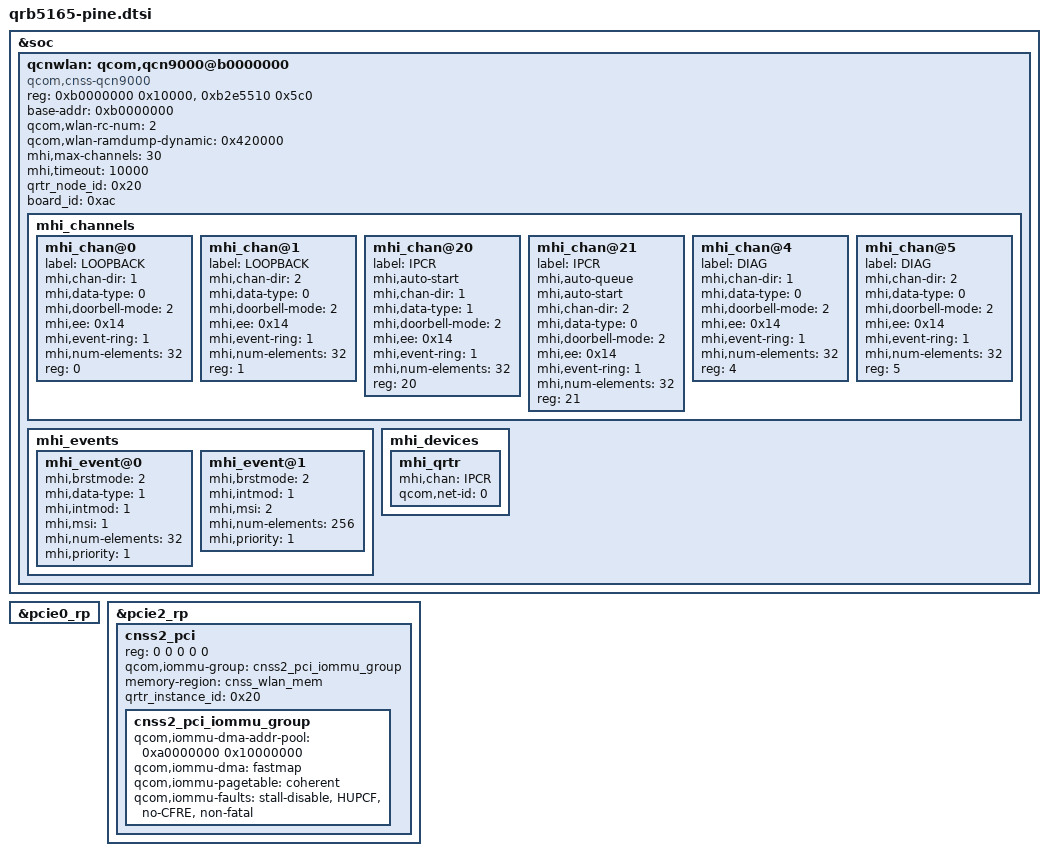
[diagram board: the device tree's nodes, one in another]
#include "qrb5165.dtsi"

&soc {
	qcnwlan: qcom,qcn9000@b0000000 {
		compatible = "qcom,cnss-qcn9000";
		reg = <0xb0000000 0x10000>,
		      <0xb2e5510 0x5c0>;
		reg-names = "smmu_iova_ipa", "tcs_cmd";
		base-addr = <0xb0000000>;
		qcom,wlan-rc-num = <2>;
		qcom,wlan-ramdump-dynamic = <0x420000>;
		mhi,max-channels = <30>;
		mhi,timeout = <10000>;
		qrtr_node_id = <0x20>;
		board_id = <0xac>;
		status="okay";

		mhi_channels {
			#address-cells = <1>;
			#size-cells = <0>;

			mhi_chan@0 {
				label = "LOOPBACK";
				mhi,chan-dir = <1>;
				mhi,data-type = <0>;
				mhi,doorbell-mode = <2>;
				mhi,ee = <0x14>;
				mhi,event-ring = <1>;
				mhi,num-elements = <32>;
				reg = <0>;
			};

			mhi_chan@1 {
				label = "LOOPBACK";
				mhi,chan-dir = <2>;
				mhi,data-type = <0>;
				mhi,doorbell-mode = <2>;
				mhi,ee = <0x14>;
				mhi,event-ring = <1>;
				mhi,num-elements = <32>;
				reg = <1>;
			};

			mhi_chan@20 {
				label = "IPCR";
				mhi,auto-start;
				mhi,chan-dir = <1>;
				mhi,data-type = <1>;
				mhi,doorbell-mode = <2>;
				mhi,ee = <0x14>;
				mhi,event-ring = <1>;
				mhi,num-elements = <32>;
				reg = <20>;
			};

			mhi_chan@21 {
				label = "IPCR";
				mhi,auto-queue;
				mhi,auto-start;
				mhi,chan-dir = <2>;
				mhi,data-type = <0>;
				mhi,doorbell-mode = <2>;
				mhi,ee = <0x14>;
				mhi,event-ring = <1>;
				mhi,num-elements = <32>;
				reg = <21>;
			};

			mhi_chan@4 {
				label = "DIAG";
				mhi,chan-dir = <1>;
				mhi,data-type = <0>;
				mhi,doorbell-mode = <2>;
				mhi,ee = <0x14>;
				mhi,event-ring = <1>;
				mhi,num-elements = <32>;
				reg = <4>;
			};

			mhi_chan@5 {
				label = "DIAG";
				mhi,chan-dir = <2>;
				mhi,data-type = <0>;
				mhi,doorbell-mode = <2>;
				mhi,ee = <0x14>;
				mhi,event-ring = <1>;
				mhi,num-elements = <32>;
				reg = <5>;
			};
		};

		mhi_events {
			mhi_event@0 {
				mhi,brstmode = <2>;
				mhi,data-type = <1>;
				mhi,intmod = <1>;
				mhi,msi = <1>;
				mhi,num-elements = <32>;
				mhi,priority = <1>;
			};

			mhi_event@1 {
				mhi,brstmode = <2>;
				mhi,intmod = <1>;
				mhi,msi = <2>;
				mhi,num-elements = <256>;
				mhi,priority = <1>;
			};
		};

		mhi_devices {
			mhi_qrtr {
				mhi,chan = "IPCR";
				qcom,net-id = <0>;
			};
		};
	};
};

&pcie0_rp {
	/delete-node/ cnss_pci;
};

&pcie2_rp {
	#address-cells = <5>;
	#size-cells = <0>;
	status = "ok";

	/delete-node/ qcom,mhi@0;

	cnss2_pci: cnss2_pci {
		reg = <0 0 0 0 0>;
		qcom,iommu-group = <&cnss2_pci_iommu_group>;
		memory-region = <&cnss_wlan_mem>;
		qrtr_instance_id = <0x20>;
		status = "ok";

		#address-cells = <1>;
		#size-cells = <1>;

		cnss2_pci_iommu_group: cnss2_pci_iommu_group {
			qcom,iommu-dma-addr-pool = <0xa0000000 0x10000000>;
			qcom,iommu-dma = "fastmap";
			qcom,iommu-pagetable = "coherent";
			qcom,iommu-faults = "stall-disable", "HUPCF", "no-CFRE",
					    "non-fatal";
		};
	};
};
